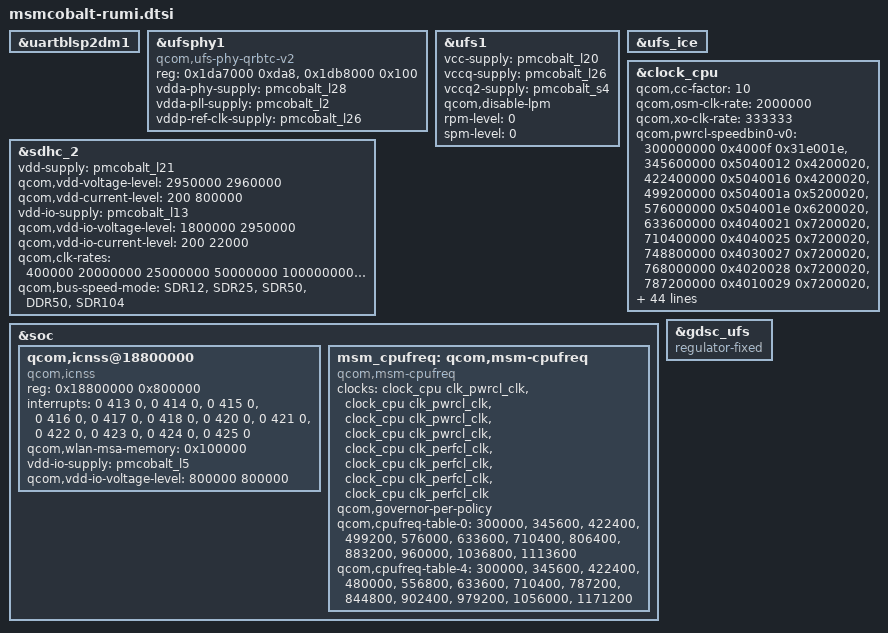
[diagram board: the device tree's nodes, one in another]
/* Copyright (c) 2015-2016, The Linux Foundation. All rights reserved.
 *
 * This program is free software; you can redistribute it and/or modify
 * it under the terms of the GNU General Public License version 2 and
 * only version 2 as published by the Free Software Foundation.
 *
 * This program is distributed in the hope that it will be useful,
 * but WITHOUT ANY WARRANTY; without even the implied warranty of
 * MERCHANTABILITY or FITNESS FOR A PARTICULAR PURPOSE.  See the
 * GNU General Public License for more details.
 */

#include "msmcobalt-pinctrl.dtsi"

&uartblsp2dm1 {
	status = "ok";
};

&ufsphy1 {
	compatible = "qcom,ufs-phy-qrbtc-v2";
	reg = <0x1da7000 0xda8>, /* PHY regs */
		<0x1db8000 0x100>; /* U11 user regs */
	reg-names = "phy_mem", "u11_user";
	vdda-phy-supply = <&pmcobalt_l28>;
	vdda-pll-supply = <&pmcobalt_l2>;
	vddp-ref-clk-supply = <&pmcobalt_l26>;
	status = "ok";
};

&ufs1 {
	vcc-supply = <&pmcobalt_l20>;
	vccq-supply = <&pmcobalt_l26>;
	vccq2-supply = <&pmcobalt_s4>;

	qcom,disable-lpm;
	rpm-level = <0>;
	spm-level = <0>;

	status = "ok";
};

&ufs_ice {
	status = "ok";
};

&sdhc_2 {
	vdd-supply = <&pmcobalt_l21>;
	qcom,vdd-voltage-level = <2950000 2960000>;
	qcom,vdd-current-level = <200 800000>;

	vdd-io-supply = <&pmcobalt_l13>;
	qcom,vdd-io-voltage-level = <1800000 2950000>;
	qcom,vdd-io-current-level = <200 22000>;

	qcom,clk-rates = <400000 20000000 25000000
				50000000 100000000 200000000>;
	qcom,bus-speed-mode = "SDR12", "SDR25", "SDR50", "DDR50", "SDR104";

	status = "ok";
};

&clock_cpu {
	qcom,cc-factor = <10>;
	qcom,osm-clk-rate = <2000000>;
	qcom,xo-clk-rate = <333333>;

	qcom,pwrcl-speedbin0-v0 =
		< 300000000 0x4000f 0x31e001e >,
		< 345600000 0x5040012 0x4200020 >,
		< 422400000 0x5040016 0x4200020 >,
		< 499200000 0x504001a 0x5200020 >,
		< 576000000 0x504001e 0x6200020 >,
		< 633600000 0x4040021 0x7200020 >,
		< 710400000 0x4040025 0x7200020 >,
		< 748800000 0x4030027 0x7200020 >,
		< 768000000 0x4020028 0x7200020 >,
		< 787200000 0x4010029 0x7200020 >,
		< 806400000 0x404002a 0x8220022 >,
		< 883200000 0x404002e 0x9250025 >,
		< 960000000 0x4040032 0xa280028 >,
		< 1036800000 0x4040036 0xb2b002b >,
		< 1113600000 0x404003a 0xc2e002e >,
		< 1190400000 0x404003e 0xc320032 >,
		< 1248000000 0x4040041 0xd340034 >,
		< 1324800000 0x4040045 0xe370037 >,
		< 1401600000 0x4040049 0xf3a003a >,
		< 1478400000 0x404004d 0x103e003e >,
		< 1574400000 0x4040052 0x10420042 >,
		< 1651200000 0x4040056 0x11450045 >,
		< 1728000000 0x404005a 0x12480048 >,
		< 1804800000 0x404005e 0x134b004b >,
		< 1881600000 0x4040062 0x144e004e >;

	qcom,perfcl-speedbin0-v0 =
		 < 300000000 0x4000f 0x3200020 >,
		 < 345600000 0x5040012 0x4200020 >,
		 < 422400000 0x5040016 0x4200020 >,
		 < 480000000 0x5040019 0x5200020 >,
		 < 556800000 0x504001d 0x6200020 >,
		 < 633600000 0x4040021 0x7200020 >,
		 < 652800000 0x4030022 0x7200020 >,
		 < 672000000 0x4020023 0x7200020 >,
		 < 691200000 0x4010024 0x7200020 >,
		 < 710400000 0x4040025 0x7200020 >,
		 < 787200000 0x4040029 0x8210021 >,
		 < 844800000 0x404002c 0x9240024 >,
		 < 902400000 0x404002f 0x9260026 >,
		 < 979200000 0x4040033 0xa290029 >,
		 < 1056000000 0x4040037 0xb2c002c >,
		 < 1171200000 0x404003d 0xc300030 >,
		 < 1248000000 0x4040041 0xd340034 >,
		 < 1324800000 0x4040045 0xe370037 >,
		 < 1401600000 0x4040049 0xf3b003b >,
		 < 1478400000 0x404004d 0xf3e003e >,
		 < 1536000000 0x4040050 0x10400040 >,
		 < 1632000000 0x4040055 0x11440044 >,
		 < 1708800000 0x4040059 0x12480048 >,
		 < 1785600000 0x404005d 0x134a004a >,
		 < 1862400000 0x4040061 0x134e004e >,
		 < 1939200000 0x4040065 0x14510051 >,
		 < 2016000000 0x4040069 0x15540054 >,
		 < 2092800000 0x404006d 0x16570057 >;
};

&soc {
	qcom,icnss@18800000 {
		compatible = "qcom,icnss";
		reg = <0x18800000 0x800000>;
		reg-names = "membase";
		interrupts = <0 413 0 /* CE0 */ >,
			     <0 414 0 /* CE1 */ >,
			     <0 415 0 /* CE2 */ >,
			     <0 416 0 /* CE3 */ >,
			     <0 417 0 /* CE4 */ >,
			     <0 418 0 /* CE5 */ >,
			     <0 420 0 /* CE6 */ >,
			     <0 421 0 /* CE7 */ >,
			     <0 422 0 /* CE8 */ >,
			     <0 423 0 /* CE9 */ >,
			     <0 424 0 /* CE10 */ >,
			     <0 425 0 /* CE11 */ >;
		qcom,wlan-msa-memory = <0x100000>;
		vdd-io-supply = <&pmcobalt_l5>;
		qcom,vdd-io-voltage-level = <800000 800000>;
	};

	msm_cpufreq: qcom,msm-cpufreq {
		compatible = "qcom,msm-cpufreq";
		clock-names = "cpu0_clk", "cpu1_clk", "cpu2_clk",
				"cpu3_clk", "cpu4_clk", "cpu5_clk",
				"cpu6_clk", "cpu7_clk";
		clocks = <&clock_cpu clk_pwrcl_clk>,
			 <&clock_cpu clk_pwrcl_clk>,
			 <&clock_cpu clk_pwrcl_clk>,
			 <&clock_cpu clk_pwrcl_clk>,
			 <&clock_cpu clk_perfcl_clk>,
			 <&clock_cpu clk_perfcl_clk>,
			 <&clock_cpu clk_perfcl_clk>,
			 <&clock_cpu clk_perfcl_clk>;

		qcom,governor-per-policy;

		qcom,cpufreq-table-0 =
			<  300000 >,
			<  345600 >,
			<  422400 >,
			<  499200 >,
			<  576000 >,
			<  633600 >,
			<  710400 >,
			<  806400 >,
			<  883200 >,
			<  960000 >,
			< 1036800 >,
			< 1113600 >;

		qcom,cpufreq-table-4 =
			<  300000 >,
			<  345600 >,
			<  422400 >,
			<  480000 >,
			<  556800 >,
			<  633600 >,
			<  710400 >,
			<  787200 >,
			<  844800 >,
			<  902400 >,
			<  979200 >,
			< 1056000 >,
			< 1171200 >;
	};
};

&gdsc_ufs {
	compatible = "regulator-fixed";
};
